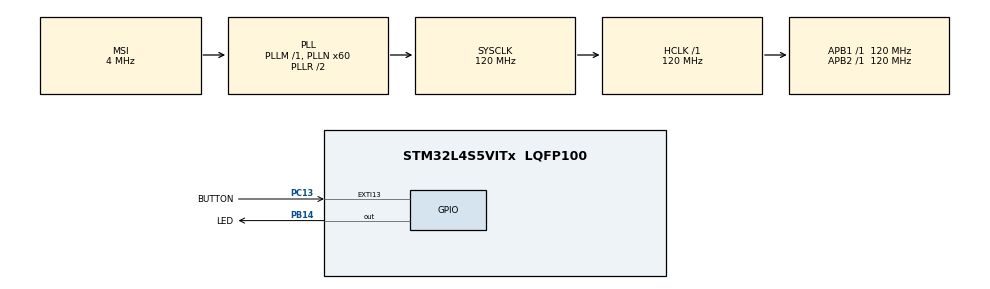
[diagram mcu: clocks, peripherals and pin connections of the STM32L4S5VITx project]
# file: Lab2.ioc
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ADC1.Channel-1\#ChannelRegularConversion=ADC_CHANNEL_TEMPSENSOR
ADC1.NbrOfConversionFlag=1
ADC1.OffsetNumber-1\#ChannelRegularConversion=ADC_OFFSET_NONE
ADC1.Rank-1\#ChannelRegularConversion=1
ADC1.SamplingTime-1\#ChannelRegularConversion=ADC_SAMPLETIME_2CYCLES_5
ADC1.master=1
Mcu.Family=STM32L4
Mcu.Name=STM32L4S5VITx
Mcu.Package=LQFP100
NVIC.PriorityGroup=NVIC_PRIORITYGROUP_4
PB14.GPIO_Label=LED
PB14.Signal=GPIO_Output
PC13.GPIO_Label=BUTTON
PC13.Signal=GPXTI13
ProjectManager.HeapSize=0x200
ProjectManager.StackSize=0x400
ProjectManager.TargetToolchain=STM32CubeIDE
RCC.ADCFreq_Value=48000000
RCC.AHBFreq_Value=120000000
RCC.APB1Freq_Value=120000000
RCC.APB1TimFreq_Value=120000000
RCC.APB2Freq_Value=120000000
RCC.APB2TimFreq_Value=120000000
RCC.CortexFreq_Value=120000000
RCC.HCLKFreq_Value=120000000
RCC.HSE_VALUE=8000000
RCC.HSI48_VALUE=48000000
RCC.HSI_VALUE=16000000
RCC.LSE_VALUE=32768
RCC.MSI_VALUE=4000000
RCC.PLLN=60
RCC.PLLSAI1N=24
RCC.SYSCLKFreq_VALUE=120000000
RCC.SYSCLKSource=RCC_SYSCLKSOURCE_PLLCLK
RCC.USBFreq_Value=48000000
RCC.VCOOutputFreq_Value=240000000
VP_ADC1_TempSens_Input.Mode=IN-TempSens
VP_ADC1_Vref_Input.Mode=IN-Vrefint
board=B-L4S5I-IOT01A

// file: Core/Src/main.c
/* USER CODE BEGIN Header */
/**
  ******************************************************************************
  * @file           : main.c
  * @brief          : Main program body
  ******************************************************************************
  * @attention
  *
  * Copyright (c) 2024 STMicroelectronics.
  * All rights reserved.
  *
  * This software is licensed under terms that can be found in the LICENSE file
  * in the root directory of this software component.
  * If no LICENSE file comes with this software, it is provided AS-IS.
  *
  ******************************************************************************
  */
/* USER CODE END Header */
#include "main.h"

/* USER CODE BEGIN PD */
//#define ADC_BUF_SIZE 8
//#define _VREFANALOG_VOLTAGE_ 3300 //ADC reference voltage in mV

#define TS_CAL1 ((uint16_t*) 0x1FFF75A8) //30 degrees C
#define TS_CAL2 ((uint16_t*) 0x1FFF75CA) //130 degrees C
#define VREFINT ((uint16_t*) 0x1FFF75AA)

/* USER CODE END PD */

ADC_HandleTypeDef hadc1;

void SystemClock_Config(void);
static void MX_GPIO_Init(void);
static void MX_ADC1_Init(void);
float Read_TEMP(float vref_current);
float Read_VREF(void);

int main(void)
{

  /* MCU Configuration--------------------------------------------------------*/

  /* Reset of all peripherals, Initializes the Flash interface and the Systick. */
  HAL_Init();

  /* Configure the system clock */
  SystemClock_Config();

  /* Initialize all configured peripherals */
  MX_GPIO_Init();
  MX_ADC1_Init();
  /* USER CODE BEGIN 2 */
  char button_status = 0;
  float temperature = 0;
  float REFERENCE_VOLTAGE = Read_VREF();
  float RESULT = 0;
  //HAL_StatusTypeDef status;
  /* USER CODE END 2 */

  /* Infinite loop */
  while (1)
  {

    /* USER CODE BEGIN 3 */
	  while(1) {
		  button_status = HAL_GPIO_ReadPin(BUTTON_GPIO_Port, BUTTON_Pin);

		  if(button_status == 0) { //button is pressed
			  HAL_GPIO_WritePin(LED_GPIO_Port, LED_Pin, GPIO_PIN_SET); //turn on the LED
			  HAL_ADC_Start(&hadc1);	//ADC conversion
			  //status = HAL_ADC_PollForConversion(&hadc1, HAL_MAX_DELAY);

			  if(HAL_ADC_PollForConversion(&hadc1, HAL_MAX_DELAY) != HAL_OK) { //checks if the ADC conversion was successful
				  Error_Handler();
			  }
			  else {
				  temperature = Read_TEMP(REFERENCE_VOLTAGE);
				  RESULT = temperature;
			  }

			  HAL_ADC_Stop(&hadc1);
		  }
		  else { //button is not pressed
			  HAL_GPIO_WritePin(LED_GPIO_Port, LED_Pin, GPIO_PIN_RESET); //turn off the LED
			  HAL_ADC_Start(&hadc1);

			  if(HAL_ADC_PollForConversion(&hadc1, HAL_MAX_DELAY) != HAL_OK) { //checks if the ADC conversion was successful
				  Error_Handler();
			  }
			  else {
				  REFERENCE_VOLTAGE = Read_VREF();
				  RESULT = REFERENCE_VOLTAGE;
			  }

			  HAL_ADC_Stop(&hadc1);
		  }
	  }
  }
  /* USER CODE END 3 */
}

float Read_TEMP(float vref_current) {
	//Swtich the channel to temp
	ADC_ChannelConfTypeDef sConfig = {0};

	sConfig.Channel = ADC_CHANNEL_TEMPSENSOR;
	sConfig.Rank = ADC_REGULAR_RANK_1;
	sConfig.SamplingTime = ADC_SAMPLETIME_640CYCLES_5;
	sConfig.SingleDiff = ADC_SINGLE_ENDED;
	sConfig.OffsetNumber = ADC_OFFSET_NONE;
	sConfig.Offset = 0;

	if (HAL_ADC_ConfigChannel(&hadc1, &sConfig) != HAL_OK)
	{
		Error_Handler();
	}

	HAL_Delay(100);

	//check for errors in ADC conversion
	if (HAL_ADC_Start(&hadc1) != HAL_OK || HAL_ADC_PollForConversion(&hadc1, 100) != HAL_OK)
	{
		// ADC start error
		Error_Handler();
	}

	//calculation or conversion
	float adcValue = HAL_ADC_GetValue(&hadc1);
	float adjustment = (adcValue * (vref_current / 3)) - *TS_CAL1; //subtract by TS_CAL1 so the curve starts at 30 (calibration)
	float m = ((float) (130 - 30)) / (*TS_CAL2 - *TS_CAL1); //calculating the slope
	float tempValue = m * (adjustment) + 30; //calculate temperature from raw ADC value (+30 because the curve starts from 30)
	return tempValue;
}

float Read_VREF(void) {
	//Switch the channel to reference voltage
	ADC_ChannelConfTypeDef sConfig = {0};

	sConfig.Channel = ADC_CHANNEL_VREFINT;
	sConfig.Rank = ADC_REGULAR_RANK_1;
	sConfig.SamplingTime = ADC_SAMPLETIME_640CYCLES_5;
	sConfig.SingleDiff = ADC_SINGLE_ENDED;
	sConfig.OffsetNumber = ADC_OFFSET_NONE;
	sConfig.Offset = 0;

	if (HAL_ADC_ConfigChannel(&hadc1, &sConfig) != HAL_OK)
	{
	    Error_Handler();
	}

	HAL_Delay(100);

	//check for errors in ADC conversion
	if (HAL_ADC_Start(&hadc1) != HAL_OK || HAL_ADC_PollForConversion(&hadc1, 100) != HAL_OK)
	{
	  // ADC start error
	  Error_Handler();
	}

	//calculation or conversion
	float adcValue = HAL_ADC_GetValue(&hadc1); //get ADC value
	float vrefValue = ((float) 3 * (*VREFINT)) / adcValue; //reference voltage calibration
	return vrefValue;
}

void SystemClock_Config(void)
{
  RCC_OscInitTypeDef RCC_OscInitStruct = {0};
  RCC_ClkInitTypeDef RCC_ClkInitStruct = {0};

  /** Configure the main internal regulator output voltage
  */
  if (HAL_PWREx_ControlVoltageScaling(PWR_REGULATOR_VOLTAGE_SCALE1_BOOST) != HAL_OK)
  {
    Error_Handler();
  }

  /** Initializes the RCC Oscillators according to the specified parameters
  * in the RCC_OscInitTypeDef structure.
  */
  RCC_OscInitStruct.OscillatorType = RCC_OSCILLATORTYPE_MSI;
  RCC_OscInitStruct.MSIState = RCC_MSI_ON;
  RCC_OscInitStruct.MSICalibrationValue = 0;
  RCC_OscInitStruct.MSIClockRange = RCC_MSIRANGE_6;
  RCC_OscInitStruct.PLL.PLLState = RCC_PLL_ON;
  RCC_OscInitStruct.PLL.PLLSource = RCC_PLLSOURCE_MSI;
  RCC_OscInitStruct.PLL.PLLM = 1;
  RCC_OscInitStruct.PLL.PLLN = 60;
  RCC_OscInitStruct.PLL.PLLP = RCC_PLLP_DIV2;
  RCC_OscInitStruct.PLL.PLLQ = RCC_PLLQ_DIV2;
  RCC_OscInitStruct.PLL.PLLR = RCC_PLLR_DIV2;
  if (HAL_RCC_OscConfig(&RCC_OscInitStruct) != HAL_OK)
  {
    Error_Handler();
  }

  /** Initializes the CPU, AHB and APB buses clocks
  */
  RCC_ClkInitStruct.ClockType = RCC_CLOCKTYPE_HCLK|RCC_CLOCKTYPE_SYSCLK
                              |RCC_CLOCKTYPE_PCLK1|RCC_CLOCKTYPE_PCLK2;
  RCC_ClkInitStruct.SYSCLKSource = RCC_SYSCLKSOURCE_PLLCLK;
  RCC_ClkInitStruct.AHBCLKDivider = RCC_SYSCLK_DIV1;
  RCC_ClkInitStruct.APB1CLKDivider = RCC_HCLK_DIV1;
  RCC_ClkInitStruct.APB2CLKDivider = RCC_HCLK_DIV1;

  if (HAL_RCC_ClockConfig(&RCC_ClkInitStruct, FLASH_LATENCY_5) != HAL_OK)
  {
    Error_Handler();
  }
}

static void MX_ADC1_Init(void)
{

  ADC_ChannelConfTypeDef sConfig = {0};

  /** Common config
  */
  hadc1.Instance = ADC1;
  hadc1.Init.ClockPrescaler = ADC_CLOCK_ASYNC_DIV1;
  hadc1.Init.Resolution = ADC_RESOLUTION_12B;
  hadc1.Init.DataAlign = ADC_DATAALIGN_RIGHT;
  hadc1.Init.ScanConvMode = ADC_SCAN_DISABLE;
  hadc1.Init.EOCSelection = ADC_EOC_SINGLE_CONV;
  hadc1.Init.LowPowerAutoWait = DISABLE;
  hadc1.Init.ContinuousConvMode = DISABLE;
  hadc1.Init.NbrOfConversion = 1;
  hadc1.Init.DiscontinuousConvMode = DISABLE;
  hadc1.Init.ExternalTrigConv = ADC_SOFTWARE_START;
  hadc1.Init.ExternalTrigConvEdge = ADC_EXTERNALTRIGCONVEDGE_NONE;
  hadc1.Init.DMAContinuousRequests = DISABLE;
  hadc1.Init.Overrun = ADC_OVR_DATA_PRESERVED;
  hadc1.Init.OversamplingMode = DISABLE;
  if (HAL_ADC_Init(&hadc1) != HAL_OK)
  {
    Error_Handler();
  }

  /** Configure Regular Channel
  */
  sConfig.Channel = ADC_CHANNEL_TEMPSENSOR;
  sConfig.Rank = ADC_REGULAR_RANK_1;
  sConfig.SamplingTime = ADC_SAMPLETIME_2CYCLES_5;
  sConfig.SingleDiff = ADC_SINGLE_ENDED;
  sConfig.OffsetNumber = ADC_OFFSET_NONE;
  sConfig.Offset = 0;
  if (HAL_ADC_ConfigChannel(&hadc1, &sConfig) != HAL_OK)
  {
    Error_Handler();
  }

}

static void MX_GPIO_Init(void)
{
  GPIO_InitTypeDef GPIO_InitStruct = {0};

  /* GPIO Ports Clock Enable */
  __HAL_RCC_GPIOC_CLK_ENABLE();
  __HAL_RCC_GPIOB_CLK_ENABLE();

  /*Configure GPIO pin Output Level */
  HAL_GPIO_WritePin(LED_GPIO_Port, LED_Pin, GPIO_PIN_RESET);

  /*Configure GPIO pin : BUTTON_Pin */
  GPIO_InitStruct.Pin = BUTTON_Pin;
  GPIO_InitStruct.Mode = GPIO_MODE_IT_RISING;
  GPIO_InitStruct.Pull = GPIO_NOPULL;
  HAL_GPIO_Init(BUTTON_GPIO_Port, &GPIO_InitStruct);

  /*Configure GPIO pin : LED_Pin */
  GPIO_InitStruct.Pin = LED_Pin;
  GPIO_InitStruct.Mode = GPIO_MODE_OUTPUT_PP;
  GPIO_InitStruct.Pull = GPIO_NOPULL;
  GPIO_InitStruct.Speed = GPIO_SPEED_FREQ_LOW;
  HAL_GPIO_Init(LED_GPIO_Port, &GPIO_InitStruct);

}

void Error_Handler(void)
{
  __disable_irq();
  while (1)
  {
  }
}
